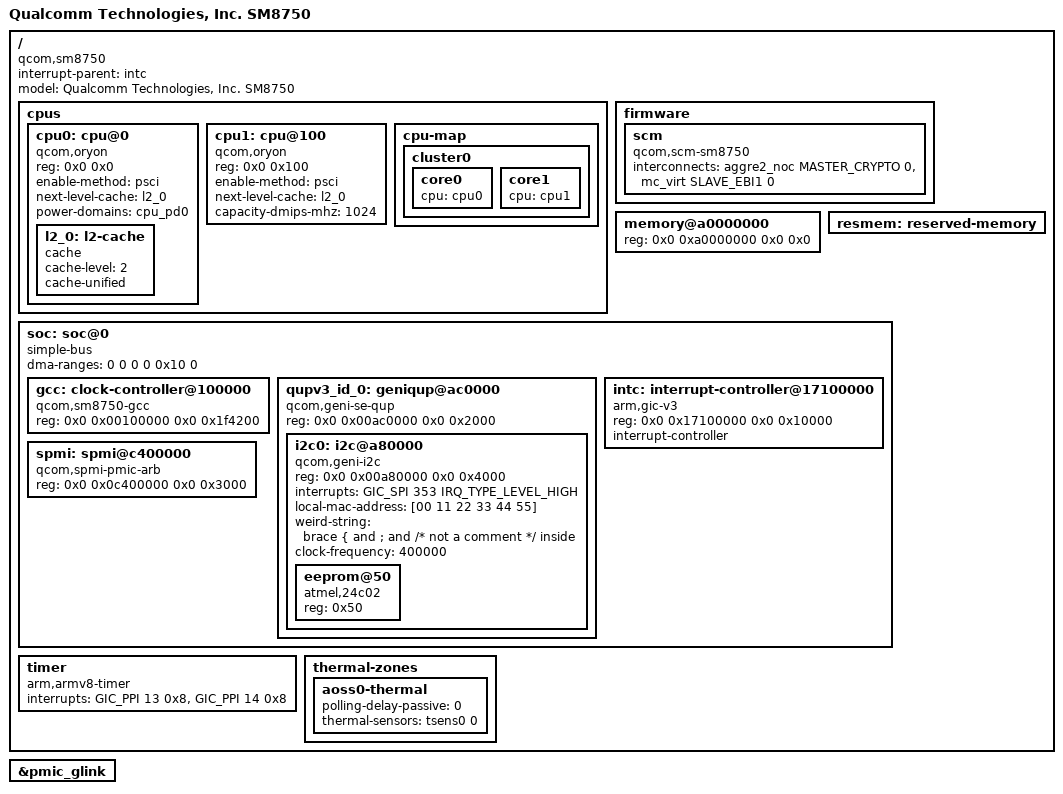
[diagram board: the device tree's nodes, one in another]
// SPDX-License-Identifier: BSD-3-Clause
/*
 * Fixture modelled on arch/arm64/boot/dts/qcom/sm8750.dtsi (Linux 6.18).
 * Trimmed, but keeps every structural feature the parser must survive:
 * multiple root blocks, &label fragments, labels, cpp macros/includes,
 * block and line comments, byte strings, multi-line cell arrays,
 * /delete-node/ and /delete-property/, and a brace inside a string.
 */

#include <dt-bindings/interrupt-controller/arm-gic.h>
#include <dt-bindings/clock/qcom,sm8750-gcc.h>

#define SOME_MACRO(a, b) \
	((a) << 4 | (b))

/dts-v1/;

/ {
	interrupt-parent = <&intc>;
	#address-cells = <2>;
	#size-cells = <2>;
	compatible = "qcom,sm8750";
	model = "Qualcomm Technologies, Inc. SM8750";

	cpus {
		#address-cells = <2>;
		#size-cells = <0>;

		cpu0: cpu@0 {
			device_type = "cpu";
			compatible = "qcom,oryon";
			reg = <0x0 0x0>;
			enable-method = "psci";
			next-level-cache = <&l2_0>;
			power-domains = <&cpu_pd0>;
			power-domain-names = "psci";

			l2_0: l2-cache {
				compatible = "cache";
				cache-level = <2>;
				cache-unified;
			};
		};

		cpu1: cpu@100 {
			device_type = "cpu";
			compatible = "qcom,oryon";
			reg = <0x0 0x100>;
			enable-method = "psci";
			next-level-cache = <&l2_0>;
		};

		cpu-map {
			cluster0 {
				core0 { cpu = <&cpu0>; };
				core1 { cpu = <&cpu1>; };
			};
		};
	};

	firmware {
		scm: scm {
			compatible = "qcom,scm-sm8750", "qcom,scm";
			interconnects = <&aggre2_noc MASTER_CRYPTO 0
					 &mc_virt SLAVE_EBI1 0>;
		};
	};

	memory@a0000000 {
		device_type = "memory";
		/* filled in by the bootloader */
		reg = <0x0 0xa0000000 0x0 0x0>;
	};

	resmem: reserved-memory {
		#address-cells = <2>;
		#size-cells = <2>;
		ranges;

		hyp_mem: hyp@80000000 {
			reg = <0x0 0x80000000 0x0 0xa00000>;
			no-map;
		};
	};

	soc: soc@0 {
		#address-cells = <2>;
		#size-cells = <2>;
		ranges = <0 0 0 0 0x10 0>;
		dma-ranges = <0 0 0 0 0x10 0>;
		compatible = "simple-bus";

		gcc: clock-controller@100000 {
			compatible = "qcom,sm8750-gcc";
			reg = <0x0 0x00100000 0x0 0x1f4200>;
			#clock-cells = <1>;
			#reset-cells = <1>;
			#power-domain-cells = <1>;
		};

		qupv3_id_0: geniqup@ac0000 {
			compatible = "qcom,geni-se-qup";
			reg = <0x0 0x00ac0000 0x0 0x2000>;
			#address-cells = <2>;
			#size-cells = <2>;
			ranges;
			status = "disabled";
			dma-names = "tx", "rx";

			i2c0: i2c@a80000 {
				compatible = "qcom,geni-i2c";
				reg = <0x0 0x00a80000 0x0 0x4000>;
				interrupts = <GIC_SPI 353 IRQ_TYPE_LEVEL_HIGH>;
				status = "disabled";
				local-mac-address = [00 11 22 33 44 55];
				weird-string = "brace { and ; and /* not a comment */ inside";
			};
		};

		intc: interrupt-controller@17100000 {
			compatible = "arm,gic-v3";
			reg = <0x0 0x17100000 0x0 0x10000>;
			#interrupt-cells = <3>;
			interrupt-controller;
		};
	};

	timer {
		compatible = "arm,armv8-timer";
		interrupts = <GIC_PPI 13 0x8>,
			     <GIC_PPI 14 0x8>;
	};
};

/* A second root block -- must merge into the first, not replace it. */
/ {
	thermal-zones {
		aoss0-thermal {
			polling-delay-passive = <0>;
			thermal-sensors = <&tsens0 0>;
		};
	};
};

/* Fragments that patch nodes defined above. */
&i2c0 {
	status = "okay";
	clock-frequency = <400000>;

	eeprom@50 {
		compatible = "atmel,24c02";
		reg = <0x50>;
	};
};

&soc {
	spmi: spmi@c400000 {
		compatible = "qcom,spmi-pmic-arb";
		reg = <0x0 0x0c400000 0x0 0x3000>;
	};
};

/* Path-reference form. */
&{/cpus/cpu@100} {
	capacity-dmips-mhz = <1024>;
};

/* Fragment whose label lives in an #include'd file we cannot see. */
&pmic_glink {
	status = "okay";
};

&qupv3_id_0 {
	status = "okay";
	/delete-property/ dma-names;
};

&resmem {
	/delete-node/ hyp@80000000;
};
